# K1921VG1T register map
Vendor: NIIET; Series: K1921VGx; File version: 2.8
CPU: other r0p1, little endian, MPU, FPU, 4 interrupt priority bits
Registers are 32-bit, read-write, reset 0x0 unless marked. A register's access mark holds for its fields unless they carry their own. Offsets are from the block's base; [hi:lo] are bit positions; lines under a group give offsets from that group; {n}, {i} and the like mark numbered series; 'fields as' and 'values as' point back to an identical list.

## ACMP0 — Analog comparator control registers
Base 0x51000000
Same registers: ACMP1 0x51001000, ACMP2 0x51002000, ACMP3 0x51003000
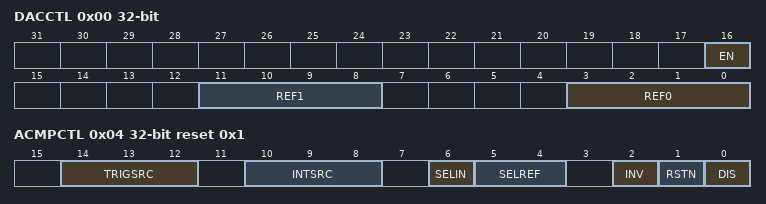
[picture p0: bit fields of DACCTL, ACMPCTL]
0x00 DACCTL — DAC control register
  [16] EN — Enable DAC for comparator
  [11:8] REF1 — Select Voltage for DAC output channel 1
  [3:0] REF0 — Select voltage for DAC output channel 0
0x04 ACMPCTL reset 0x1 — ACMP control register
  [14:12] TRIGSRC — Select trigger event
  [10:8] INTSRC — Select interrupt source
  [6] SELIN — Select input for IN0
    0=INPUT (Selects IN_P); 1=TEST (Select test out from DAC)
  [5:4] SELREF — Select reference voltage
    0=EXT (Select IN_N as reference voltage); 1=DAC_CH0 (Select DAC channel 0 as reference voltage); 2=DAC_CH1 (Select DAC channel 1 as reference voltage); 3=RSRV (Reserved (unpredicted result))
  [2] INV — Inverse output
  [1] RSTN — Reset comparator (active low)
  [0] DIS — Disable comparator
0x08 ACSTATUS ro — ACMP status
  [0] STATE — Comparator output pin status
0x10 INTEN — Interrupt enable
  [0] CMP
0x14 RIS ro — Raw interrupt status
  [0] CMP
0x18 MIS ro — Masked interrupt status
  [0] CMP
0x1C ICLR wo — Clear interrupt status
  [0] CMP

## I2S0 — I2S control registers
Base 0x51006000
Same registers: I2S1 0x51007000
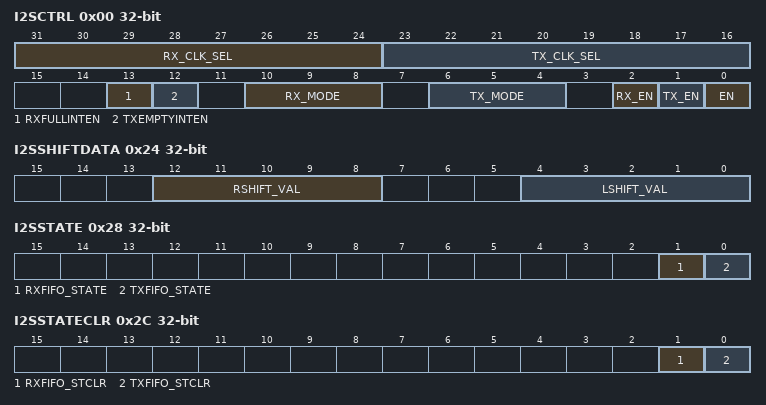
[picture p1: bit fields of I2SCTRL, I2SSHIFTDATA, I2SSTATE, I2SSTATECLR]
0x00 I2SCTRL — I2S Control register
  [31:24] RX_CLK_SEL — Receiver clock source select
  [23:16] TX_CLK_SEL — Transmitter clock source select
  [13] RXFULLINTEN — Receiver buffer full interrupt enable
  [12] TXEMPTYINTEN — Transmit buffer empty interrupt enable
  [10:8] RX_MODE — I2S receiver mode
    0=Phillips (I2S Philips protocol mode); 1=MSB-justified protocol mode; 2=LSB-justified protocol mode; 3=PCM Short Frame protocol mode; 7=PCM Long Frame protocol mode
  [6:4] TX_MODE — I2S transmitter mode
    values as RX_MODE
  [2] RX_EN — I2S Receiver enable
  [1] TX_EN — I2S Transmitter enable
  [0] EN — Enable I2S block
0x04 I2SCLKDIV1 — I2S Clock Divider 1 register
  [31:0] VAL — Divider 1 value
0x08 I2SCLKDIV2 — I2S Clock Divider 2 register
  [31:0] VAL — Divider 2 value
0x0C I2SFRMCTRL1 — I2S Frame control 1 register
  [8:0] VAL — Frame Control 1 Value
0x10 I2SFRMCTRL2 — I2S Frame control 2 register
  [8:0] VAL — Frame Control 2 Value
0x14 I2SRECBUFUSED ro — I2S Receiver Buffer Counts register
  [3:0] VAL — Buffer counter value
0x18 I2STRANSDATA wo — I2S Transmitter Data register
  [31:0] VAL — Data to transmit value
0x1C I2SMCLKDIV — I2S Master Clock Divider register
  [31:0] VAL — Master clock divider value
0x20 I2SRECDATA ro — I2S Receiver Data register
  [31:0] VAL — Received data value
0x24 I2SSHIFTDATA
  [12:8] RSHIFT_VAL — Number of counts to be shifted right
  [4:0] LSHIFT_VAL — Number of counts to be shifted left
0x28 I2SSTATE ro
  [1] RXFIFO_STATE — Receiver FIFO status
  [0] TXFIFO_STATE — Transmiter FIFO status
0x2C I2SSTATECLR wo — I2S State Clear register
  [1] RXFIFO_STCLR — Receiver FIFO status clear
  [0] TXFIFO_STCLR — Transmiter FIFO status clear
0x30 I2STRBUFUSED ro — I2S Transmitter Buffer Counts register
  [3:0] VAL — Buffer counter value

## TMR0 — Timer control registers
Base 0x51008000
Same registers: TMR{n} {0x51008000+0x1000*n} (n=1..15)
0x00 CTRL — Timer control register
  [12:9] OUTEN — CAPCOM3 block output enable
  [8] CLKSEL — Clock Source Select
    0=SysClk (Select system Clk); 1=ExtClk (Select External Clk)
  [7] DMARXSTOP — Stop Timer when RX DMA channel ends all transactions
  [6] DMATXSTOP — Stop Timer when TX DMA channel ends all transactions
  [5:4] MODE — Count mode
    0=Stop (Timer is Stopped); 1=Up (Timer count Up); 2=Multiple (Timer count is multiple Up); 3=UpDown (Timer count is multiple Up - Down)
  [2] CLR wo — Timer Clear
  [1:0] FREESOFT — Emulation mode bits - select the behavior of the time-base counter during emulation events
    0=StopAtCLK (stop timer at next CLK tact); 1=StopAtOverload (stop timer when overload); 2=NoStop (endless count)
0x04 COUNT — Current value timer register
  [31:0] VAL — Current timer value
0x08 CLKDIV — Clock divider register
  [31:0] VAL
0x0C PERIOD — Timer period register
  [31:0] VAL
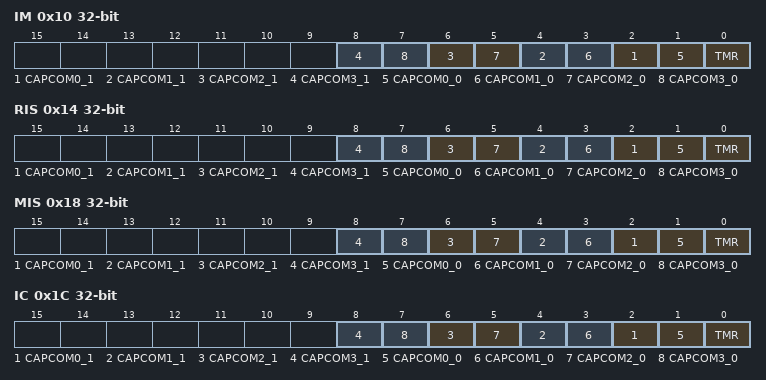
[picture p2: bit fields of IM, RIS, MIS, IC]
0x10 IM — Interrupt mask register
  [2n+2] CAPCOM{n}_1 (n=0..3) — Capcom{2n+1} Interrupt Enable
  [2n+1] CAPCOM{n}_0 (n=0..3) — Capcom{2n} Interrupt Enable
  [0] TMR — Timer Interrupt Enable
0x14 RIS ro — Raw Interrupt Status register
  [2n+2] CAPCOM{n}_1 (n=0..3) — Capcom{2n+1} Interrupt Status
  [2n+1] CAPCOM{n}_0 (n=0..3) — Capcom{2n} Interrupt Status
  [0] TMR — Timer Interrupt Status
0x18 MIS ro — Masked Interrupt Status register
  fields as RIS
0x1C IC wo — Clear Interrupt Status register
  [2n+2] CAPCOM{n}_1 (n=0..3) — Capcom{2n+1} Interrupt Clear
  [2n+1] CAPCOM{n}_0 (n=0..3) — Capcom{2n} Interrupt Clear
  [0] TMR — Timer Interrupt Clear
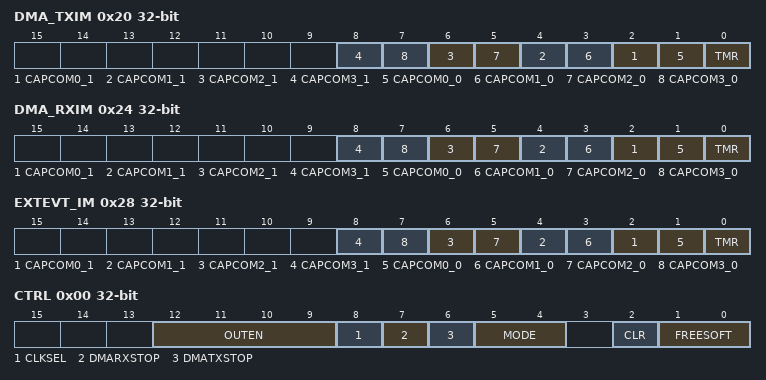
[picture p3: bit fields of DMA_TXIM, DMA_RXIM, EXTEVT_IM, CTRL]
0x20 DMA_TXIM — DMA TX request mask register
  [2n+2] CAPCOM{n}_1 (n=0..3) — Capcom{2n+1} DMA TX Request Enable
  [2n+1] CAPCOM{n}_0 (n=0..3) — Capcom{2n} DMA TX Request Enable
  [0] TMR — Timer DMA TX Request Enable
0x24 DMA_RXIM — DMA RX request mask register
  [2n+2] CAPCOM{n}_1 (n=0..3) — Capcom{2n+1} DMA RX Request Enable
  [2n+1] CAPCOM{n}_0 (n=0..3) — Capcom{2n} DMA RX Request Enable
  [0] TMR — Timer DMA RX Request Enable
0x28 EXTEVT_IM — External Event mask register
  [2n+2] CAPCOM{n}_1 (n=0..3) — Capcom{2n+1} External Event Request Enable
  [2n+1] CAPCOM{n}_0 (n=0..3) — Capcom{2n} External Event Request Enable
  [0] TMR — Timer External Event Request Enable
{0x100+0x10*i} CAPCOM[{i}] (i=0..3) group
  0x00 CTRL reset 0x20 — Capture / Compare Control register
    [15:14] CAPMODE — Capture Mode
    [13:12] CCISEL — Capture / Compare Input Select
    [10] SCCI ro — Synchronized Capture / Compare Input
    [8] CAP — Capture Mode
    [7:5] OUTMODE — Output Mode
    [3] CCI ro — Capture / Compare Input
    [2] OUT — Output
    [1] OVF — Capture Overflow
  0x04 VAL0 — Capture/Compare Value 0 register
    [31:0] VAL
  0x08 VAL1 — Capture/Compare Value 1 register
    [31:0] VAL
